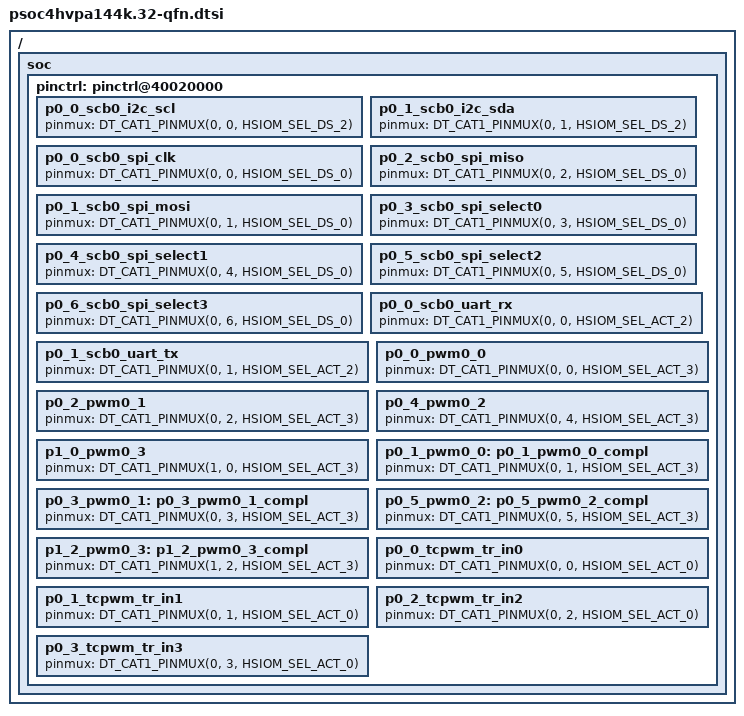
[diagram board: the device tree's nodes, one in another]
/*
 * SPDX-FileCopyrightText: Copyright (c) 2026 Infineon Technologies AG,
 * SPDX-FileCopyrightText: or an affiliate of Infineon Technologies AG. All rights reserved.
 *
 * SPDX-License-Identifier: Apache-2.0
 */

#include <zephyr/dt-bindings/gpio/gpio.h>
#include <zephyr/dt-bindings/pinctrl/ifx_cat1-pinctrl.h>
#include "psoc4hvpa144k.dtsi"

/ {
	soc {
		pinctrl: pinctrl@40020000 {
			/* scb_i2c_scl */
			/omit-if-no-ref/ p0_0_scb0_i2c_scl: p0_0_scb0_i2c_scl {
				pinmux = <DT_CAT1_PINMUX(0, 0, HSIOM_SEL_DS_2)>;
			};

			/* scb_i2c_sda */
			/omit-if-no-ref/ p0_1_scb0_i2c_sda: p0_1_scb0_i2c_sda {
				pinmux = <DT_CAT1_PINMUX(0, 1, HSIOM_SEL_DS_2)>;
			};

			/* scb_spi_clk */
			/omit-if-no-ref/ p0_0_scb0_spi_clk: p0_0_scb0_spi_clk {
				pinmux = <DT_CAT1_PINMUX(0, 0, HSIOM_SEL_DS_0)>;
			};

			/* scb_spi_miso */
			/omit-if-no-ref/ p0_2_scb0_spi_miso: p0_2_scb0_spi_miso {
				pinmux = <DT_CAT1_PINMUX(0, 2, HSIOM_SEL_DS_0)>;
			};

			/* scb_spi_mosi */
			/omit-if-no-ref/ p0_1_scb0_spi_mosi: p0_1_scb0_spi_mosi {
				pinmux = <DT_CAT1_PINMUX(0, 1, HSIOM_SEL_DS_0)>;
			};

			/* scb_spi_select0 */
			/omit-if-no-ref/ p0_3_scb0_spi_select0: p0_3_scb0_spi_select0 {
				pinmux = <DT_CAT1_PINMUX(0, 3, HSIOM_SEL_DS_0)>;
			};

			/* scb_spi_select1 */
			/omit-if-no-ref/ p0_4_scb0_spi_select1: p0_4_scb0_spi_select1 {
				pinmux = <DT_CAT1_PINMUX(0, 4, HSIOM_SEL_DS_0)>;
			};

			/* scb_spi_select2 */
			/omit-if-no-ref/ p0_5_scb0_spi_select2: p0_5_scb0_spi_select2 {
				pinmux = <DT_CAT1_PINMUX(0, 5, HSIOM_SEL_DS_0)>;
			};

			/* scb_spi_select3 */
			/omit-if-no-ref/ p0_6_scb0_spi_select3: p0_6_scb0_spi_select3 {
				pinmux = <DT_CAT1_PINMUX(0, 6, HSIOM_SEL_DS_0)>;
			};

			/* scb_uart_rx */
			/omit-if-no-ref/ p0_0_scb0_uart_rx: p0_0_scb0_uart_rx {
				pinmux = <DT_CAT1_PINMUX(0, 0, HSIOM_SEL_ACT_2)>;
			};

			/* scb_uart_tx */
			/omit-if-no-ref/ p0_1_scb0_uart_tx: p0_1_scb0_uart_tx {
				pinmux = <DT_CAT1_PINMUX(0, 1, HSIOM_SEL_ACT_2)>;
			};

			/* PWM tcpwm_line */
			/omit-if-no-ref/ p0_0_pwm0_0: p0_0_pwm0_0 {
				pinmux = <DT_CAT1_PINMUX(0, 0, HSIOM_SEL_ACT_3)>;
			};

			/omit-if-no-ref/ p0_2_pwm0_1: p0_2_pwm0_1 {
				pinmux = <DT_CAT1_PINMUX(0, 2, HSIOM_SEL_ACT_3)>;
			};

			/omit-if-no-ref/ p0_4_pwm0_2: p0_4_pwm0_2 {
				pinmux = <DT_CAT1_PINMUX(0, 4, HSIOM_SEL_ACT_3)>;
			};

			/omit-if-no-ref/ p1_0_pwm0_3: p1_0_pwm0_3 {
				pinmux = <DT_CAT1_PINMUX(1, 0, HSIOM_SEL_ACT_3)>;
			};

			/* PWM tcpwm_line_compl */
			/omit-if-no-ref/ p0_1_pwm0_0: p0_1_pwm0_0_compl {
				pinmux = <DT_CAT1_PINMUX(0, 1, HSIOM_SEL_ACT_3)>;
			};

			/omit-if-no-ref/ p0_3_pwm0_1: p0_3_pwm0_1_compl {
				pinmux = <DT_CAT1_PINMUX(0, 3, HSIOM_SEL_ACT_3)>;
			};

			/omit-if-no-ref/ p0_5_pwm0_2: p0_5_pwm0_2_compl {
				pinmux = <DT_CAT1_PINMUX(0, 5, HSIOM_SEL_ACT_3)>;
			};

			/omit-if-no-ref/ p1_2_pwm0_3: p1_2_pwm0_3_compl {
				pinmux = <DT_CAT1_PINMUX(1, 2, HSIOM_SEL_ACT_3)>;
			};

			/* PWM tcpwm_tr_in */
			/omit-if-no-ref/ p0_0_tcpwm_tr_in0: p0_0_tcpwm_tr_in0 {
				pinmux = <DT_CAT1_PINMUX(0, 0, HSIOM_SEL_ACT_0)>;
			};

			/omit-if-no-ref/ p0_1_tcpwm_tr_in1: p0_1_tcpwm_tr_in1 {
				pinmux = <DT_CAT1_PINMUX(0, 1, HSIOM_SEL_ACT_0)>;
			};

			/omit-if-no-ref/ p0_2_tcpwm_tr_in2: p0_2_tcpwm_tr_in2 {
				pinmux = <DT_CAT1_PINMUX(0, 2, HSIOM_SEL_ACT_0)>;
			};

			/omit-if-no-ref/ p0_3_tcpwm_tr_in3: p0_3_tcpwm_tr_in3 {
				pinmux = <DT_CAT1_PINMUX(0, 3, HSIOM_SEL_ACT_0)>;
			};
		};
	};
};
